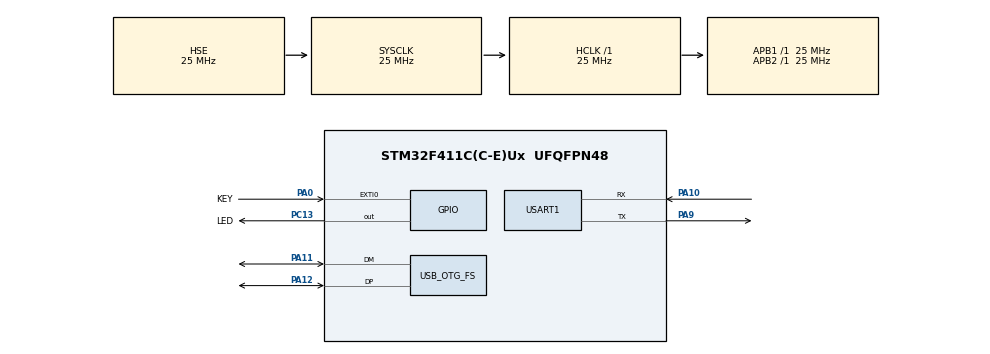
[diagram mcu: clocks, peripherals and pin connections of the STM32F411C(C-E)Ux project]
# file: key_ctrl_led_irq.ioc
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FREERTOS.Tasks01=defaultTask,24,128,StartDefaultTask,Default,NULL,Dynamic,NULL,NULL
Mcu.Family=STM32F4
Mcu.Name=STM32F411C(C-E)Ux
Mcu.Package=UFQFPN48
NVIC.EXTI0_IRQn=true\:5\:0\:false\:false\:true\:true\:true\:true\:true
NVIC.OTG_FS_IRQn=true\:5\:0\:false\:false\:true\:true\:false\:true\:true
NVIC.PriorityGroup=NVIC_PRIORITYGROUP_4
NVIC.TIM2_IRQn=true\:15\:0\:false\:false\:true\:false\:false\:true\:true
NVIC.TIM4_IRQn=true\:5\:0\:false\:false\:true\:true\:true\:true\:true
NVIC.TimeBase=TIM2_IRQn
NVIC.TimeBaseIP=TIM2
NVIC.USART1_IRQn=true\:5\:0\:false\:false\:true\:true\:true\:true\:true
PA0-WKUP.GPIO_Label=KEY
PA0-WKUP.GPIO_ModeDefaultEXTI=GPIO_MODE_IT_RISING_FALLING
PA0-WKUP.GPIO_PuPd=GPIO_NOPULL
PA0-WKUP.Signal=GPXTI0
PA10.Mode=Asynchronous
PA10.Signal=USART1_RX
PA11.Mode=Device_Only
PA11.Signal=USB_OTG_FS_DM
PA12.Mode=Device_Only
PA12.Signal=USB_OTG_FS_DP
PA13.Mode=Serial_Wire
PA13.Signal=SYS_JTMS-SWDIO
PA14.Mode=Serial_Wire
PA14.Signal=SYS_JTCK-SWCLK
PA9.Mode=Asynchronous
PA9.Signal=USART1_TX
PC13-ANTI_TAMP.GPIO_Label=LED
PC13-ANTI_TAMP.PinState=GPIO_PIN_SET
PC13-ANTI_TAMP.Signal=GPIO_Output
PC14-OSC32_IN.Mode=LSE-External-Oscillator
PC14-OSC32_IN.Signal=RCC_OSC32_IN
PC15-OSC32_OUT.Mode=LSE-External-Oscillator
PC15-OSC32_OUT.Signal=RCC_OSC32_OUT
PH0\ -\ OSC_IN.Mode=HSE-External-Oscillator
PH0\ -\ OSC_IN.Signal=RCC_OSC_IN
PH1\ -\ OSC_OUT.Mode=HSE-External-Oscillator
PH1\ -\ OSC_OUT.Signal=RCC_OSC_OUT
ProjectManager.HeapSize=0x800
ProjectManager.StackSize=0x400
ProjectManager.TargetToolchain=MDK-ARM V5.32
RCC.48MHZClocksFreq_Value=48000000
RCC.AHBFreq_Value=25000000
RCC.APB1Freq_Value=25000000
RCC.APB1TimFreq_Value=25000000
RCC.APB2Freq_Value=25000000
RCC.APB2TimFreq_Value=25000000
RCC.CortexFreq_Value=25000000
RCC.HCLKFreq_Value=25000000
RCC.HSE_VALUE=25000000
RCC.HSI_VALUE=16000000
RCC.PLLM=15
RCC.PLLN=144
RCC.PLLQ=5
RCC.RCC_RTC_Clock_Source=RCC_RTCCLKSOURCE_LSE
RCC.RCC_RTC_Clock_SourceVirtual=RCC_RTCCLKSOURCE_LSE
RCC.SYSCLKFreq_VALUE=25000000
RCC.SYSCLKSource=RCC_SYSCLKSOURCE_HSE
RCC.VCOOutputFreq_Value=240000000
TIM4.Period=2000-1
TIM4.Prescaler=2500-1
USART1.VirtualMode=VM_ASYNC
USB_DEVICE.CLASS_NAME_FS=CDC
USB_DEVICE.VirtualMode=Cdc
USB_DEVICE.VirtualModeFS=Cdc_FS
USB_OTG_FS.VirtualMode=Device_Only
VP_FREERTOS_VS_CMSIS_V2.Mode=CMSIS_V2
VP_RTC_VS_RTC_Activate.Mode=RTC_Enabled
VP_SYS_VS_tim2.Mode=TIM2
VP_TIM4_VS_ClockSourceINT.Mode=Internal
VP_USB_DEVICE_VS_USB_DEVICE_CDC_FS.Mode=CDC_FS
board=custom

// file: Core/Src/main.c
/* USER CODE BEGIN Header */
/**
  ******************************************************************************
  * @file           : main.c
  * @brief          : Main program body
  ******************************************************************************
  * @attention
  *
  * Copyright (c) 2024 STMicroelectronics.
  * All rights reserved.
  *
  * This software is licensed under terms that can be found in the LICENSE file
  * in the root directory of this software component.
  * If no LICENSE file comes with this software, it is provided AS-IS.
  *
  ******************************************************************************
  */
/* USER CODE END Header */
#include "main.h"
#include "cmsis_os.h"
#include "rtc.h"
#include "tim.h"
#include "usart.h"
#include "usb_device.h"
#include "gpio.h"

void SystemClock_Config(void);
void MX_FREERTOS_Init(void);
/* USER CODE BEGIN PFP */
extern void led_timeout_callback(void);

/* USER CODE END PFP */

int main(void)
{

  /* MCU Configuration--------------------------------------------------------*/

  /* Reset of all peripherals, Initializes the Flash interface and the Systick. */
  HAL_Init();

  /* Configure the system clock */
  SystemClock_Config();

  /* Initialize all configured peripherals */
  MX_GPIO_Init();
  MX_RTC_Init();
  MX_USART1_UART_Init();
  MX_TIM4_Init();

  /* Init scheduler */
  osKernelInitialize();

  /* Call init function for freertos objects (in cmsis_os2.c) */
  MX_FREERTOS_Init();

  /* Start scheduler */
  osKernelStart();

  /* We should never get here as control is now taken by the scheduler */

  /* Infinite loop */
  while (1)
  {

  }
}

void SystemClock_Config(void)
{
  RCC_OscInitTypeDef RCC_OscInitStruct = {0};
  RCC_ClkInitTypeDef RCC_ClkInitStruct = {0};

  /** Configure the main internal regulator output voltage
  */
  __HAL_RCC_PWR_CLK_ENABLE();
  __HAL_PWR_VOLTAGESCALING_CONFIG(PWR_REGULATOR_VOLTAGE_SCALE1);

  /** Initializes the RCC Oscillators according to the specified parameters
  * in the RCC_OscInitTypeDef structure.
  */
  RCC_OscInitStruct.OscillatorType = RCC_OSCILLATORTYPE_HSE|RCC_OSCILLATORTYPE_LSE;
  RCC_OscInitStruct.HSEState = RCC_HSE_ON;
  RCC_OscInitStruct.LSEState = RCC_LSE_ON;
  RCC_OscInitStruct.PLL.PLLState = RCC_PLL_ON;
  RCC_OscInitStruct.PLL.PLLSource = RCC_PLLSOURCE_HSE;
  RCC_OscInitStruct.PLL.PLLM = 15;
  RCC_OscInitStruct.PLL.PLLN = 144;
  RCC_OscInitStruct.PLL.PLLP = RCC_PLLP_DIV2;
  RCC_OscInitStruct.PLL.PLLQ = 5;
  if (HAL_RCC_OscConfig(&RCC_OscInitStruct) != HAL_OK)
  {
    Error_Handler();
  }

  /** Initializes the CPU, AHB and APB buses clocks
  */
  RCC_ClkInitStruct.ClockType = RCC_CLOCKTYPE_HCLK|RCC_CLOCKTYPE_SYSCLK
                              |RCC_CLOCKTYPE_PCLK1|RCC_CLOCKTYPE_PCLK2;
  RCC_ClkInitStruct.SYSCLKSource = RCC_SYSCLKSOURCE_HSE;
  RCC_ClkInitStruct.AHBCLKDivider = RCC_SYSCLK_DIV1;
  RCC_ClkInitStruct.APB1CLKDivider = RCC_HCLK_DIV1;
  RCC_ClkInitStruct.APB2CLKDivider = RCC_HCLK_DIV1;

  if (HAL_RCC_ClockConfig(&RCC_ClkInitStruct, FLASH_LATENCY_0) != HAL_OK)
  {
    Error_Handler();
  }
}

void HAL_TIM_PeriodElapsedCallback(TIM_HandleTypeDef *htim)
{
  if (htim->Instance == TIM2) {
    HAL_IncTick();
  }
  /* USER CODE BEGIN Callback 1 */
  if (htim->Instance == TIM4)
  {
    led_timeout_callback();
  }
  /* USER CODE END Callback 1 */
}

void Error_Handler(void)
{
  __disable_irq();
  while (1)
  {
  }
}

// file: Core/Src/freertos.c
/* USER CODE BEGIN Header */
/**
  ******************************************************************************
  * File Name          : freertos.c
  * Description        : Code for freertos applications
  ******************************************************************************
  * @attention
  *
  * Copyright (c) 2024 STMicroelectronics.
  * All rights reserved.
  *
  * This software is licensed under terms that can be found in the LICENSE file
  * in the root directory of this software component.
  * If no LICENSE file comes with this software, it is provided AS-IS.
  *
  ******************************************************************************
  */
/* USER CODE END Header */

#include "FreeRTOS.h"
#include "task.h"
#include "main.h"
#include "cmsis_os.h"

/* USER CODE BEGIN Includes */
#include "uart_printf.h"

/* USER CODE END Includes */

/* Definitions for defaultTask */
osThreadId_t defaultTaskHandle;
const osThreadAttr_t defaultTask_attributes = {
  .name = "defaultTask",
  .stack_size = 128 * 4,
  .priority = (osPriority_t) osPriorityNormal,
};

/* USER CODE BEGIN FunctionPrototypes */
extern void key_ctrl_led_irq_tasks_init(void);

/* USER CODE END FunctionPrototypes */

void StartDefaultTask(void *argument);

extern void MX_USB_DEVICE_Init(void);
void MX_FREERTOS_Init(void); /* (MISRA C 2004 rule 8.1) */

void MX_FREERTOS_Init(void) {

  /* Create the thread(s) */
  /* creation of defaultTask */
  defaultTaskHandle = osThreadNew(StartDefaultTask, NULL, &defaultTask_attributes);

  /* USER CODE BEGIN RTOS_THREADS */
  /* add threads, ... */
  key_ctrl_led_irq_tasks_init();
  /* USER CODE END RTOS_THREADS */

}

void StartDefaultTask(void *argument)
{
  /* init code for USB_DEVICE */
  MX_USB_DEVICE_Init();
  /* USER CODE BEGIN StartDefaultTask */
  osPrintf("Hello World!\r\n");

  /* Infinite loop */
  for(;;)
  {
    osDelay(1);
  }
  /* USER CODE END StartDefaultTask */
}
